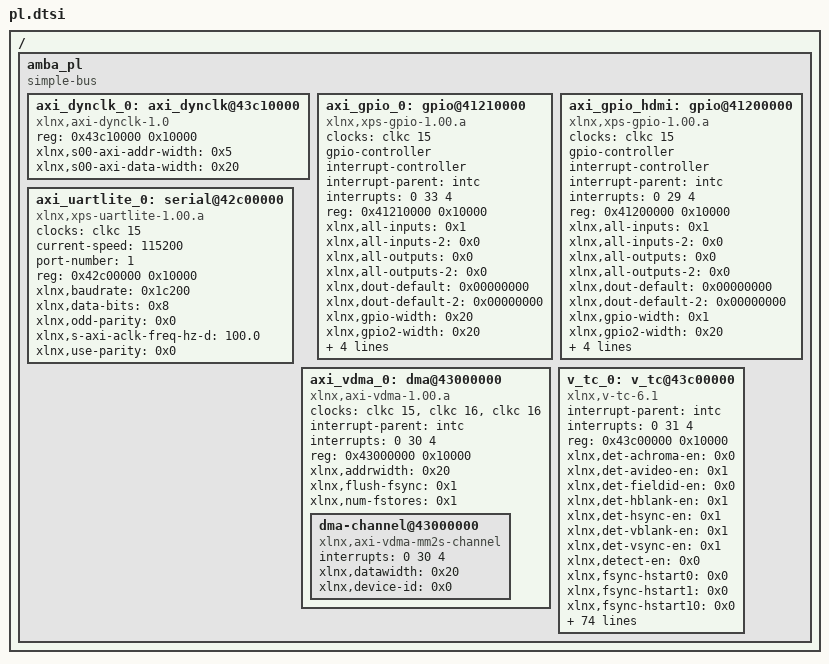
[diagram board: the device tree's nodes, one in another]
/*
 * CAUTION: This file is automatically generated by Xilinx.
 * Version:  
 * Today is: Sat Mar 30 14:48:04 2024
 */


/ {
	amba_pl: amba_pl {
		#address-cells = <1>;
		#size-cells = <1>;
		compatible = "simple-bus";
		ranges ;
		axi_dynclk_0: axi_dynclk@43c10000 {
			compatible = "xlnx,axi-dynclk-1.0";
			reg = <0x43c10000 0x10000>;
			xlnx,s00-axi-addr-width = <0x5>;
			xlnx,s00-axi-data-width = <0x20>;
		};
		axi_gpio_0: gpio@41210000 {
			#gpio-cells = <3>;
			#interrupt-cells = <2>;
			clock-names = "s_axi_aclk";
			clocks = <&clkc 15>;
			compatible = "xlnx,xps-gpio-1.00.a";
			gpio-controller ;
			interrupt-controller ;
			interrupt-names = "ip2intc_irpt";
			interrupt-parent = <&intc>;
			interrupts = <0 33 4>;
			reg = <0x41210000 0x10000>;
			xlnx,all-inputs = <0x1>;
			xlnx,all-inputs-2 = <0x0>;
			xlnx,all-outputs = <0x0>;
			xlnx,all-outputs-2 = <0x0>;
			xlnx,dout-default = <0x00000000>;
			xlnx,dout-default-2 = <0x00000000>;
			xlnx,gpio-width = <0x20>;
			xlnx,gpio2-width = <0x20>;
			xlnx,interrupt-present = <0x1>;
			xlnx,is-dual = <0x0>;
			xlnx,tri-default = <0xFFFFFFFF>;
			xlnx,tri-default-2 = <0xFFFFFFFF>;
		};
		axi_gpio_hdmi: gpio@41200000 {
			#gpio-cells = <3>;
			#interrupt-cells = <2>;
			clock-names = "s_axi_aclk";
			clocks = <&clkc 15>;
			compatible = "xlnx,xps-gpio-1.00.a";
			gpio-controller ;
			interrupt-controller ;
			interrupt-names = "ip2intc_irpt";
			interrupt-parent = <&intc>;
			interrupts = <0 29 4>;
			reg = <0x41200000 0x10000>;
			xlnx,all-inputs = <0x1>;
			xlnx,all-inputs-2 = <0x0>;
			xlnx,all-outputs = <0x0>;
			xlnx,all-outputs-2 = <0x0>;
			xlnx,dout-default = <0x00000000>;
			xlnx,dout-default-2 = <0x00000000>;
			xlnx,gpio-width = <0x1>;
			xlnx,gpio2-width = <0x20>;
			xlnx,interrupt-present = <0x1>;
			xlnx,is-dual = <0x0>;
			xlnx,tri-default = <0xFFFFFFFF>;
			xlnx,tri-default-2 = <0xFFFFFFFF>;
		};
		axi_uartlite_0: serial@42c00000 {
			clock-names = "s_axi_aclk";
			clocks = <&clkc 15>;
			compatible = "xlnx,xps-uartlite-1.00.a";
			current-speed = <115200>;
			device_type = "serial";
			port-number = <1>;
			reg = <0x42c00000 0x10000>;
			xlnx,baudrate = <0x1c200>;
			xlnx,data-bits = <0x8>;
			xlnx,odd-parity = <0x0>;
			xlnx,s-axi-aclk-freq-hz-d = "100.0";
			xlnx,use-parity = <0x0>;
		};
		axi_vdma_0: dma@43000000 {
			#dma-cells = <1>;
			clock-names = "s_axi_lite_aclk m_axi_mm2s_aclk m_axi_mm2s_aclk";
			clocks = <&clkc 15>, <&clkc 16>, <&clkc 16>;
			compatible = "xlnx,axi-vdma-1.00.a";
			interrupt-names = "mm2s_introut";
			interrupt-parent = <&intc>;
			interrupts = <0 30 4>;
			reg = <0x43000000 0x10000>;
			xlnx,addrwidth = <0x20>;
			xlnx,flush-fsync = <0x1>;
			xlnx,num-fstores = <0x1>;
			dma-channel@43000000 {
				compatible = "xlnx,axi-vdma-mm2s-channel";
				interrupts = <0 30 4>;
				xlnx,datawidth = <0x20>;
				xlnx,device-id = <0x0>;
			};
		};
		v_tc_0: v_tc@43c00000 {
			compatible = "xlnx,v-tc-6.1";
			interrupt-names = "irq";
			interrupt-parent = <&intc>;
			interrupts = <0 31 4>;
			reg = <0x43c00000 0x10000>;
			xlnx,det-achroma-en = <0x0>;
			xlnx,det-avideo-en = <0x1>;
			xlnx,det-fieldid-en = <0x0>;
			xlnx,det-hblank-en = <0x1>;
			xlnx,det-hsync-en = <0x1>;
			xlnx,det-vblank-en = <0x1>;
			xlnx,det-vsync-en = <0x1>;
			xlnx,detect-en = <0x0>;
			xlnx,fsync-hstart0 = <0x0>;
			xlnx,fsync-hstart1 = <0x0>;
			xlnx,fsync-hstart10 = <0x0>;
			xlnx,fsync-hstart11 = <0x0>;
			xlnx,fsync-hstart12 = <0x0>;
			xlnx,fsync-hstart13 = <0x0>;
			xlnx,fsync-hstart14 = <0x0>;
			xlnx,fsync-hstart15 = <0x0>;
			xlnx,fsync-hstart2 = <0x0>;
			xlnx,fsync-hstart3 = <0x0>;
			xlnx,fsync-hstart4 = <0x0>;
			xlnx,fsync-hstart5 = <0x0>;
			xlnx,fsync-hstart6 = <0x0>;
			xlnx,fsync-hstart7 = <0x0>;
			xlnx,fsync-hstart8 = <0x0>;
			xlnx,fsync-hstart9 = <0x0>;
			xlnx,fsync-vstart0 = <0x0>;
			xlnx,fsync-vstart1 = <0x0>;
			xlnx,fsync-vstart10 = <0x0>;
			xlnx,fsync-vstart11 = <0x0>;
			xlnx,fsync-vstart12 = <0x0>;
			xlnx,fsync-vstart13 = <0x0>;
			xlnx,fsync-vstart14 = <0x0>;
			xlnx,fsync-vstart15 = <0x0>;
			xlnx,fsync-vstart2 = <0x0>;
			xlnx,fsync-vstart3 = <0x0>;
			xlnx,fsync-vstart4 = <0x0>;
			xlnx,fsync-vstart5 = <0x0>;
			xlnx,fsync-vstart6 = <0x0>;
			xlnx,fsync-vstart7 = <0x0>;
			xlnx,fsync-vstart8 = <0x0>;
			xlnx,fsync-vstart9 = <0x0>;
			xlnx,gen-achroma-en = <0x0>;
			xlnx,gen-achroma-polarity = <0x1>;
			xlnx,gen-auto-switch = <0x0>;
			xlnx,gen-avideo-en = <0x1>;
			xlnx,gen-avideo-polarity = <0x1>;
			xlnx,gen-cparity = <0x0>;
			xlnx,gen-f0-vblank-hend = <0x320>;
			xlnx,gen-f0-vblank-hstart = <0x320>;
			xlnx,gen-f0-vframe-size = <0x274>;
			xlnx,gen-f0-vsync-hend = <0x320>;
			xlnx,gen-f0-vsync-hstart = <0x320>;
			xlnx,gen-f0-vsync-vend = <0x25c>;
			xlnx,gen-f0-vsync-vstart = <0x258>;
			xlnx,gen-f1-vblank-hend = <0x320>;
			xlnx,gen-f1-vblank-hstart = <0x320>;
			xlnx,gen-f1-vframe-size = <0x274>;
			xlnx,gen-f1-vsync-hend = <0x320>;
			xlnx,gen-f1-vsync-hstart = <0x320>;
			xlnx,gen-f1-vsync-vend = <0x25c>;
			xlnx,gen-f1-vsync-vstart = <0x258>;
			xlnx,gen-fieldid-en = <0x0>;
			xlnx,gen-fieldid-polarity = <0x1>;
			xlnx,gen-hactive-size = <0x320>;
			xlnx,gen-hblank-en = <0x1>;
			xlnx,gen-hblank-polarity = <0x1>;
			xlnx,gen-hframe-size = <0x420>;
			xlnx,gen-hsync-en = <0x1>;
			xlnx,gen-hsync-end = <0x3c8>;
			xlnx,gen-hsync-polarity = <0x1>;
			xlnx,gen-hsync-start = <0x348>;
			xlnx,gen-interlaced = <0x0>;
			xlnx,gen-vactive-size = <0x258>;
			xlnx,gen-vblank-en = <0x1>;
			xlnx,gen-vblank-polarity = <0x1>;
			xlnx,gen-video-format = <0x2>;
			xlnx,gen-vsync-en = <0x1>;
			xlnx,gen-vsync-polarity = <0x1>;
			xlnx,generate-en = <0x1>;
			xlnx,has-axi4-lite = <0x1>;
			xlnx,has-intc-if = <0x0>;
			xlnx,interlace-en = <0x0>;
			xlnx,max-lines = <0x1000>;
			xlnx,max-pixels = <0x1000>;
			xlnx,num-fsyncs = <0x1>;
			xlnx,sync-en = <0x0>;
		};
	};
};
